# ESP32-C6 register map
Vendor: ESPRESSIF SYSTEMS (SHANGHAI) CO., LTD.; Series: ESP32 C-Series; File version: 12
CPU: RV32IMAC r0p0, little endian, no MPU, no FPU, 0 interrupt priority bits
Address unit: 32 bits
Registers are 32-bit, read-write, reset 0x0 unless marked. A register's access mark holds for its fields unless they carry their own. Offsets are from the block's base; [hi:lo] are bit positions; lines under a group give offsets from that group; {n}, {i} and the like mark numbered series.

## IEEE802154 — IEEE802154 Peripheral
Base 0x600A3000
0x00 COMMAND
  [7:0] OPCODE
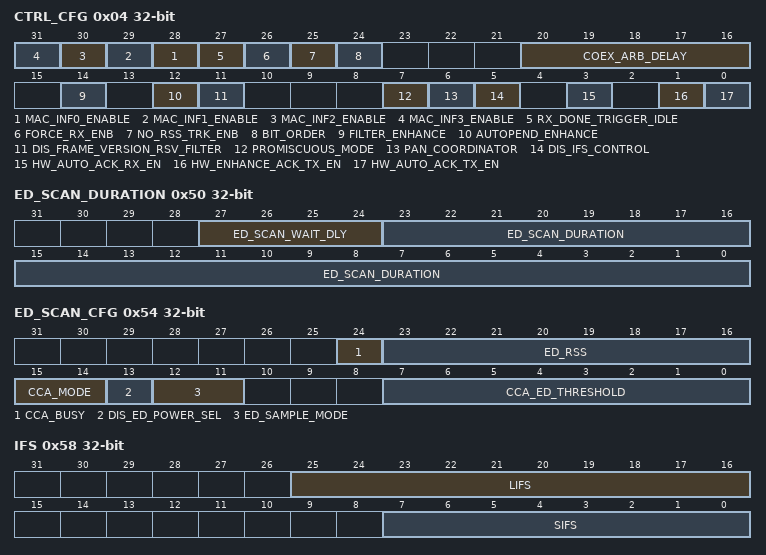
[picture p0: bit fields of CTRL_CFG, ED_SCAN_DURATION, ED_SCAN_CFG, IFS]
0x04 CTRL_CFG
  [n+28] MAC_INF{n}_ENABLE (n=0..3), [27] RX_DONE_TRIGGER_IDLE, [26] FORCE_RX_ENB, [25] NO_RSS_TRK_ENB, [24] BIT_ORDER, [20:16] COEX_ARB_DELAY, [14] FILTER_ENHANCE, [12] AUTOPEND_ENHANCE, [11] DIS_FRAME_VERSION_RSV_FILTER, [7] PROMISCUOUS_MODE, [6] PAN_COORDINATOR, [5] DIS_IFS_CONTROL, [3] HW_AUTO_ACK_RX_EN, [1] HW_ENHANCE_ACK_TX_EN, [0] HW_AUTO_ACK_TX_EN
{0x8+0x10*i} INF{i} group (i=0..3) — Cluster INF%s, containing INF?_EXTEND_ADDR0, INF?_EXTEND_ADDR1, INF?_PAN_ID, INF?_SHORT_ADDR
  0x00 SHORT_ADDR
    [15:0] SHORT_ADDR
  0x04 PAN_ID
    [15:0] PAN_ID
  0x08 EXTEND_ADDR0
  0x0C EXTEND_ADDR1
0x48 CHANNEL
  [6:0] HOP
0x4C TX_POWER
  [4:0] TX_POWER
0x50 ED_SCAN_DURATION
  [27:24] ED_SCAN_WAIT_DLY, [23:0] ED_SCAN_DURATION
0x54 ED_SCAN_CFG
  [24] CCA_BUSY, [23:16] ED_RSS, [15:14] CCA_MODE, [13] DIS_ED_POWER_SEL, [12:11] ED_SAMPLE_MODE, [7:0] CCA_ED_THRESHOLD
0x58 IFS
  [25:16] LIFS, [7:0] SIFS
0x5C ACK_TIMEOUT
  [15:0] ACK_TIMEOUT
0x60 EVENT_EN
  [12:0] EVENT_EN
0x64 EVENT_STATUS
  [12:0] EVENT_STATUS
0x68 RX_ABORT_INTR_CTRL
  [30:0] RX_ABORT_INTR_CTRL
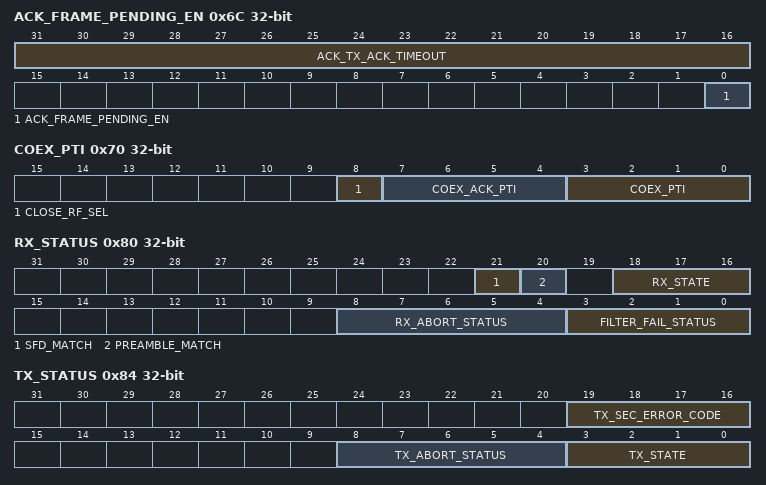
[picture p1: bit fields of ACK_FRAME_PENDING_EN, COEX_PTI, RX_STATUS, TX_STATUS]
0x6C ACK_FRAME_PENDING_EN
  [31:16] ACK_TX_ACK_TIMEOUT, [0] ACK_FRAME_PENDING_EN
0x70 COEX_PTI
  [8] CLOSE_RF_SEL, [7:4] COEX_ACK_PTI, [3:0] COEX_PTI
0x74 CORE_DUMMY_DATA
0x78 TX_ABORT_INTERRUPT_CONTROL
  [30:0] TX_ABORT_INTERRUPT_CONTROL
0x7C ENHANCE_ACK_CFG
  [31:0] TX_ENH_ACK_GENERATE_DONE_NOTIFY
0x80 RX_STATUS
  [21] SFD_MATCH, [20] PREAMBLE_MATCH, [18:16] RX_STATE, [8:4] RX_ABORT_STATUS, [3:0] FILTER_FAIL_STATUS
0x84 TX_STATUS
  [19:16] TX_SEC_ERROR_CODE, [8:4] TX_ABORT_STATUS, [3:0] TX_STATE
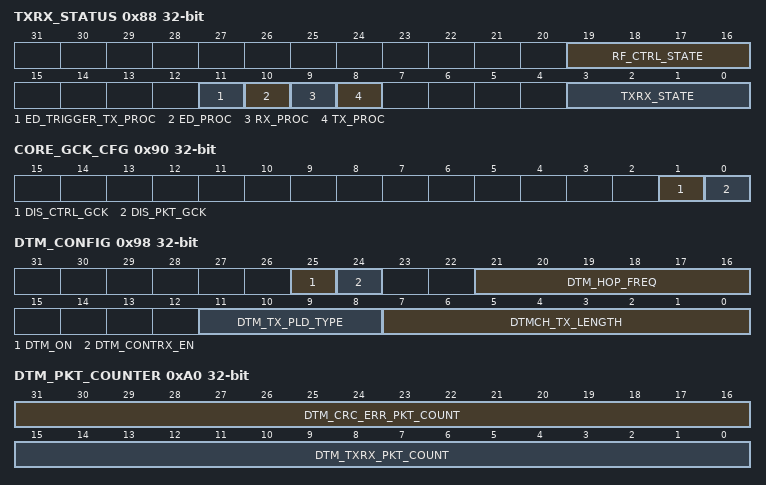
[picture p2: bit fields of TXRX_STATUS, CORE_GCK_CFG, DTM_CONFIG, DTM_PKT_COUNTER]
0x88 TXRX_STATUS
  [19:16] RF_CTRL_STATE, [11] ED_TRIGGER_TX_PROC, [10] ED_PROC, [9] RX_PROC, [8] TX_PROC, [3:0] TXRX_STATE
0x8C TX_CCM_SCHEDULE_STATUS
  [30:0] TX_CCM_SCHEDULE_STATUS
0x90 CORE_GCK_CFG
  [1] DIS_CTRL_GCK, [0] DIS_PKT_GCK
0x94 TEST_CONTROL
  [0] WRONG_CRC
0x98 DTM_CONFIG
  [25] DTM_ON, [24] DTM_CONTRX_EN, [21:16] DTM_HOP_FREQ, [11:8] DTM_TX_PLD_TYPE, [7:0] DTMCH_TX_LENGTH
0x9C DTM_TX_PKT_CONFIG
  [15:0] DTM_TX_PKT_THRESHOLD
0xA0 DTM_PKT_COUNTER
  [31:16] DTM_CRC_ERR_PKT_COUNT, [15:0] DTM_TXRX_PKT_COUNT
0xA4 RX_LENGTH
  [6:0] RX_LENGTH
0xA8 TIME0 group — Cluster TIME%s, containing TIME?_THRESHOLD, TIME?_VALUE
  0x00 THRESHOLD
    [31:0] TIMER0_THRESHOLD
  0x04 VALUE
    [31:0] TIMER0_VALUE
0xB0 TIME1 group — Cluster TIME%s, containing TIME?_THRESHOLD, TIME?_VALUE
  0x00 THRESHOLD
    [31:0] TIMER0_THRESHOLD
  0x04 VALUE
    [31:0] TIMER0_VALUE
0xB8 CLK_COUNTER_MATCH_VAL
  [15:0] CLK_COUNT_MATCH_VAL
0xBC CLK_COUNTER
  [15:0] CLK_625US_CNT
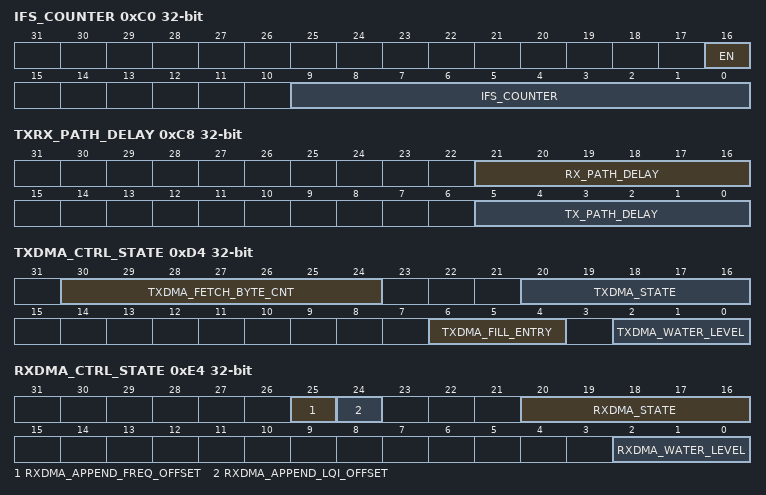
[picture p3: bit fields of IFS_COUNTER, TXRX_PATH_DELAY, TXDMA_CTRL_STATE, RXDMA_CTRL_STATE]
0xC0 IFS_COUNTER
  [16] EN, [9:0] IFS_COUNTER
0xC4 SFD_WAIT_SYMBOL
  [3:0] NUM
0xC8 TXRX_PATH_DELAY
  [21:16] RX_PATH_DELAY, [5:0] TX_PATH_DELAY
0xCC BB_CLK
  [4:0] FREQ_MINUS_1
0xD0 TXDMA_ADDR
0xD4 TXDMA_CTRL_STATE
  [30:24] TXDMA_FETCH_BYTE_CNT, [20:16] TXDMA_STATE, [6:4] TXDMA_FILL_ENTRY, [2:0] TXDMA_WATER_LEVEL
0xD8 TXDMA_ERR
  [3:0] TXDMA_ERR
0xE0 RXDMA_ADDR
0xE4 RXDMA_CTRL_STATE
  [25] RXDMA_APPEND_FREQ_OFFSET, [24] RXDMA_APPEND_LQI_OFFSET, [20:16] RXDMA_STATE, [2:0] RXDMA_WATER_LEVEL
0xE8 RXDMA_ERR
  [3:0] RXDMA_ERR
0xF0 DMA_GCK_CFG
  [0] DMA_GCK_CFG
0xF4 DMA_DUMMY
  [31:0] DATA
0x100 PAON_DELAY
  [9:0] PAON_DELAY
0x104 TXON_DELAY
  [9:0] TXON_DELAY
0x108 TXEN_STOP_DELAY
  [5:0] TXEN_STOP_DLY
0x10C TXOFF_DELAY
  [5:0] TXOFF_DELAY
0x110 RXON_DELAY
  [10:0] RXON_DELAY
0x114 TXRX_SWITCH_DELAY
  [9:0] TXRX_SWITCH_DELAY
0x118 CONT_RX_DELAY
  [5:0] CONT_RX_DELAY
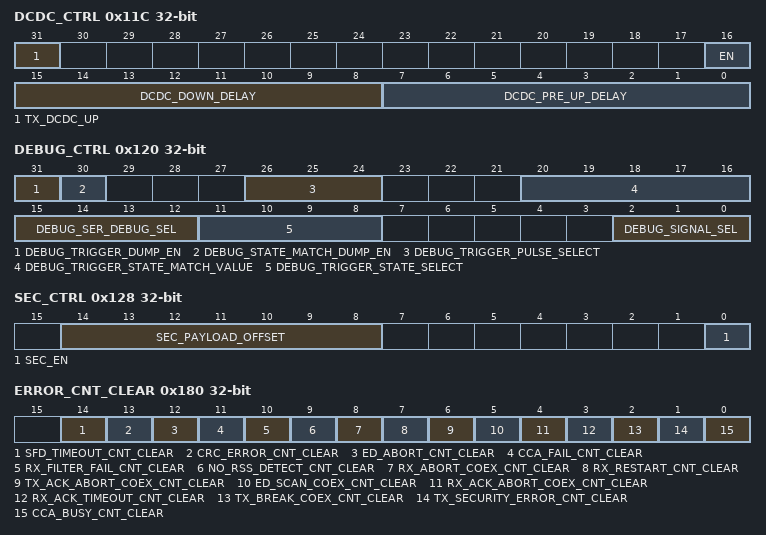
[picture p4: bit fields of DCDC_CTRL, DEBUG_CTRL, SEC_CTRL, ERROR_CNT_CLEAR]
0x11C DCDC_CTRL
  [31] TX_DCDC_UP, [16] EN, [15:8] DCDC_DOWN_DELAY, [7:0] DCDC_PRE_UP_DELAY
0x120 DEBUG_CTRL
  [31] DEBUG_TRIGGER_DUMP_EN, [30] DEBUG_STATE_MATCH_DUMP_EN, [26:24] DEBUG_TRIGGER_PULSE_SELECT, [20:16] DEBUG_TRIGGER_STATE_MATCH_VALUE, [15:12] DEBUG_SER_DEBUG_SEL, [11:8] DEBUG_TRIGGER_STATE_SELECT, [2:0] DEBUG_SIGNAL_SEL
0x128 SEC_CTRL
  [14:8] SEC_PAYLOAD_OFFSET, [0] SEC_EN
0x12C SEC_EXTEND_ADDRESS0
0x130 SEC_EXTEND_ADDRESS1
{0x134+4i} SEC_KEY{i} (i=0..3)
  [31:0] SEC_KEY0
0x144 SFD_TIMEOUT_CNT
  [15:0] SFD_TIMEOUT_CNT
0x148 CRC_ERROR_CNT
  [15:0] CRC_ERROR_CNT
0x14C ED_ABORT_CNT
  [15:0] ED_ABORT_CNT
0x150 CCA_FAIL_CNT
  [15:0] CCA_FAIL_CNT
0x154 RX_FILTER_FAIL_CNT
  [15:0] RX_FILTER_FAIL_CNT
0x158 NO_RSS_DETECT_CNT
  [15:0] NO_RSS_DETECT_CNT
0x15C RX_ABORT_COEX_CNT
  [15:0] RX_ABORT_COEX_CNT
0x160 RX_RESTART_CNT
  [15:0] RX_RESTART_CNT
0x164 TX_ACK_ABORT_COEX_CNT
  [15:0] TX_ACK_ABORT_COEX_CNT
0x168 ED_SCAN_COEX_CNT
  [15:0] ED_SCAN_COEX_CNT
0x16C RX_ACK_ABORT_COEX_CNT
  [15:0] RX_ACK_ABORT_COEX_CNT
0x170 RX_ACK_TIMEOUT_CNT
  [15:0] RX_ACK_TIMEOUT_CNT
0x174 TX_BREAK_COEX_CNT
  [15:0] TX_BREAK_COEX_CNT
0x178 TX_SECURITY_ERROR_CNT
  [15:0] TX_SECURITY_ERROR_CNT
0x17C CCA_BUSY_CNT
  [15:0] CCA_BUSY_CNT
0x180 ERROR_CNT_CLEAR
  [14] SFD_TIMEOUT_CNT_CLEAR, [13] CRC_ERROR_CNT_CLEAR, [12] ED_ABORT_CNT_CLEAR, [11] CCA_FAIL_CNT_CLEAR, [10] RX_FILTER_FAIL_CNT_CLEAR, [9] NO_RSS_DETECT_CNT_CLEAR, [8] RX_ABORT_COEX_CNT_CLEAR, [7] RX_RESTART_CNT_CLEAR, [6] TX_ACK_ABORT_COEX_CNT_CLEAR, [5] ED_SCAN_COEX_CNT_CLEAR, [4] RX_ACK_ABORT_COEX_CNT_CLEAR, [3] RX_ACK_TIMEOUT_CNT_CLEAR, [2] TX_BREAK_COEX_CNT_CLEAR, [1] TX_SECURITY_ERROR_CNT_CLEAR, [0] CCA_BUSY_CNT_CLEAR
0x184 MAC_DATE — AES version control register
